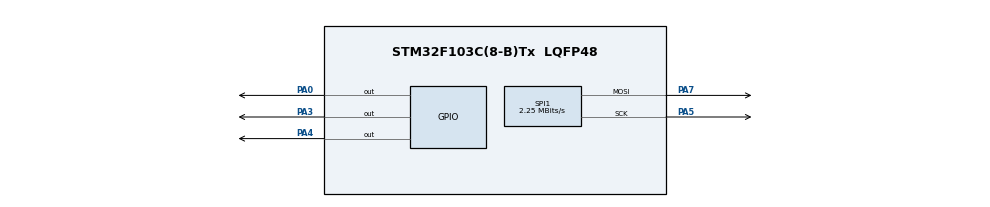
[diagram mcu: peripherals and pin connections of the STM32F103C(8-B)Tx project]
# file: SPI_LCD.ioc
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Mcu.Family=STM32F1
Mcu.Name=STM32F103C(8-B)Tx
Mcu.Package=LQFP48
NVIC.PriorityGroup=NVIC_PRIORITYGROUP_4
PA0-WKUP.Signal=GPIO_Output
PA13.Mode=Serial_Wire
PA13.Signal=SYS_JTMS-SWDIO
PA14.Mode=Serial_Wire
PA14.Signal=SYS_JTCK-SWCLK
PA3.Signal=GPIO_Output
PA4.Signal=GPIO_Output
PA5.Mode=TX_Only_Simplex_Unidirect_Master
PA5.Signal=SPI1_SCK
PA7.Mode=TX_Only_Simplex_Unidirect_Master
PA7.Signal=SPI1_MOSI
PD0-OSC_IN.Mode=HSE-External-Oscillator
PD0-OSC_IN.Signal=RCC_OSC_IN
PD1-OSC_OUT.Mode=HSE-External-Oscillator
PD1-OSC_OUT.Signal=RCC_OSC_OUT
ProjectManager.HeapSize=0x200
ProjectManager.StackSize=0x400
ProjectManager.TargetToolchain=MDK-ARM V5.27
RCC.AHBFreq_Value=72000000
RCC.APB1CLKDivider=RCC_HCLK_DIV2
RCC.APB1Freq_Value=36000000
RCC.APB1TimFreq_Value=72000000
RCC.APB2Freq_Value=72000000
RCC.APB2TimFreq_Value=72000000
RCC.HCLKFreq_Value=72000000
RCC.PLLMUL=RCC_PLL_MUL9
RCC.PLLSourceVirtual=RCC_PLLSOURCE_HSE
RCC.SYSCLKFreq_VALUE=72000000
RCC.SYSCLKSource=RCC_SYSCLKSOURCE_PLLCLK
RCC.USBFreq_Value=72000000
SPI1.BaudRatePrescaler=SPI_BAUDRATEPRESCALER_32
SPI1.CalculateBaudRate=2.25 MBits/s
SPI1.Direction=SPI_DIRECTION_2LINES
SPI1.Mode=SPI_MODE_MASTER
SPI1.VirtualType=VM_MASTER
board=custom

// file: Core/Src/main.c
/* USER CODE BEGIN Header */
/**
  ******************************************************************************
  * @file           : main.c
  * @brief          : Main program body
  ******************************************************************************
  * @attention
  *
  * <h2><center>&copy; Copyright (c) 2021 STMicroelectronics.
  * All rights reserved.</center></h2>
  *
  * This software component is licensed by ST under BSD 3-Clause license,
  * the "License"; You may not use this file except in compliance with the
  * License. You may obtain a copy of the License at:
  *                        opensource.org/licenses/BSD-3-Clause
  *
  ******************************************************************************
  */
/* USER CODE END Header */
#include "main.h"

/* USER CODE BEGIN Includes */
#include "stdio.h"					//For printf & scanf
#include "font.h"					//5x8 font used in this project
#include "LCD.h"					//All the functions that we have written in order to work wtih "Nokia 5110" LCD
#include "string.h"					//To use strings
/* USER CODE END Includes */

void SystemClock_Config(void);
static void MX_GPIO_Init(void);
static void MX_SPI1_Init(void);

int main(void)
{

  /* MCU Configuration--------------------------------------------------------*/

  /* Reset of all peripherals, Initializes the Flash interface and the Systick. */

  LL_APB2_GRP1_EnableClock(LL_APB2_GRP1_PERIPH_AFIO);
  LL_APB1_GRP1_EnableClock(LL_APB1_GRP1_PERIPH_PWR);

  NVIC_SetPriorityGrouping(NVIC_PRIORITYGROUP_4);

  /* System interrupt init*/

  /** NOJTAG: JTAG-DP Disabled and SW-DP Enabled
  */
  LL_GPIO_AF_Remap_SWJ_NOJTAG();

  /* Configure the system clock */
  SystemClock_Config();

  /* Initialize all configured peripherals */
  MX_GPIO_Init();
  MX_SPI1_Init();
  /* USER CODE BEGIN 2 */
	LL_SPI_Enable(SPI1);

	LL_mDelay(10);
	LCD_init();						//Initialize the LCD
	LCD_cls();						//clear the screen of the LCD

LCD_goto_xy(20,4);					//change positon of writing cursor

printf("%s","123");					//write on the LCD using prinf function

  /* USER CODE END 2 */

  /* Infinite loop */
  while (1)
  {

}
}

void SystemClock_Config(void)
{
  LL_FLASH_SetLatency(LL_FLASH_LATENCY_2);
  while(LL_FLASH_GetLatency()!= LL_FLASH_LATENCY_2)
  {
  }
  LL_RCC_HSE_Enable();

   /* Wait till HSE is ready */
  while(LL_RCC_HSE_IsReady() != 1)
  {

  }
  LL_RCC_PLL_ConfigDomain_SYS(LL_RCC_PLLSOURCE_HSE_DIV_1, LL_RCC_PLL_MUL_9);
  LL_RCC_PLL_Enable();

   /* Wait till PLL is ready */
  while(LL_RCC_PLL_IsReady() != 1)
  {

  }
  LL_RCC_SetAHBPrescaler(LL_RCC_SYSCLK_DIV_1);
  LL_RCC_SetAPB1Prescaler(LL_RCC_APB1_DIV_2);
  LL_RCC_SetAPB2Prescaler(LL_RCC_APB2_DIV_1);
  LL_RCC_SetSysClkSource(LL_RCC_SYS_CLKSOURCE_PLL);

   /* Wait till System clock is ready */
  while(LL_RCC_GetSysClkSource() != LL_RCC_SYS_CLKSOURCE_STATUS_PLL)
  {

  }
  LL_Init1msTick(72000000);
  LL_SetSystemCoreClock(72000000);
}

static void MX_SPI1_Init(void)
{

  LL_SPI_InitTypeDef SPI_InitStruct = {0};

  LL_GPIO_InitTypeDef GPIO_InitStruct = {0};

  /* Peripheral clock enable */
  LL_APB2_GRP1_EnableClock(LL_APB2_GRP1_PERIPH_SPI1);

  LL_APB2_GRP1_EnableClock(LL_APB2_GRP1_PERIPH_GPIOA);
  /**SPI1 GPIO Configuration
  PA5   ------> SPI1_SCK
  PA7   ------> SPI1_MOSI
  */
  GPIO_InitStruct.Pin = LL_GPIO_PIN_5|LL_GPIO_PIN_7;
  GPIO_InitStruct.Mode = LL_GPIO_MODE_ALTERNATE;
  GPIO_InitStruct.Speed = LL_GPIO_SPEED_FREQ_HIGH;
  GPIO_InitStruct.OutputType = LL_GPIO_OUTPUT_PUSHPULL;
  LL_GPIO_Init(GPIOA, &GPIO_InitStruct);

  /* SPI1 parameter configuration*/
  SPI_InitStruct.TransferDirection = LL_SPI_FULL_DUPLEX;
  SPI_InitStruct.Mode = LL_SPI_MODE_MASTER;
  SPI_InitStruct.DataWidth = LL_SPI_DATAWIDTH_8BIT;
  SPI_InitStruct.ClockPolarity = LL_SPI_POLARITY_LOW;
  SPI_InitStruct.ClockPhase = LL_SPI_PHASE_1EDGE;
  SPI_InitStruct.NSS = LL_SPI_NSS_SOFT;
  SPI_InitStruct.BaudRate = LL_SPI_BAUDRATEPRESCALER_DIV32;
  SPI_InitStruct.BitOrder = LL_SPI_MSB_FIRST;
  SPI_InitStruct.CRCCalculation = LL_SPI_CRCCALCULATION_DISABLE;
  SPI_InitStruct.CRCPoly = 10;
  LL_SPI_Init(SPI1, &SPI_InitStruct);

}

static void MX_GPIO_Init(void)
{
  LL_GPIO_InitTypeDef GPIO_InitStruct = {0};

  /* GPIO Ports Clock Enable */
  LL_APB2_GRP1_EnableClock(LL_APB2_GRP1_PERIPH_GPIOD);
  LL_APB2_GRP1_EnableClock(LL_APB2_GRP1_PERIPH_GPIOA);

  /**/
  LL_GPIO_ResetOutputPin(GPIOA, LL_GPIO_PIN_0|LL_GPIO_PIN_3|LL_GPIO_PIN_4);

  /**/
  GPIO_InitStruct.Pin = LL_GPIO_PIN_0|LL_GPIO_PIN_3|LL_GPIO_PIN_4;
  GPIO_InitStruct.Mode = LL_GPIO_MODE_OUTPUT;
  GPIO_InitStruct.Speed = LL_GPIO_SPEED_FREQ_LOW;
  GPIO_InitStruct.OutputType = LL_GPIO_OUTPUT_PUSHPULL;
  LL_GPIO_Init(GPIOA, &GPIO_InitStruct);

}

void Error_Handler(void)
{
}

/************************ (C) COPYRIGHT STMicroelectronics *****END OF FILE****/
